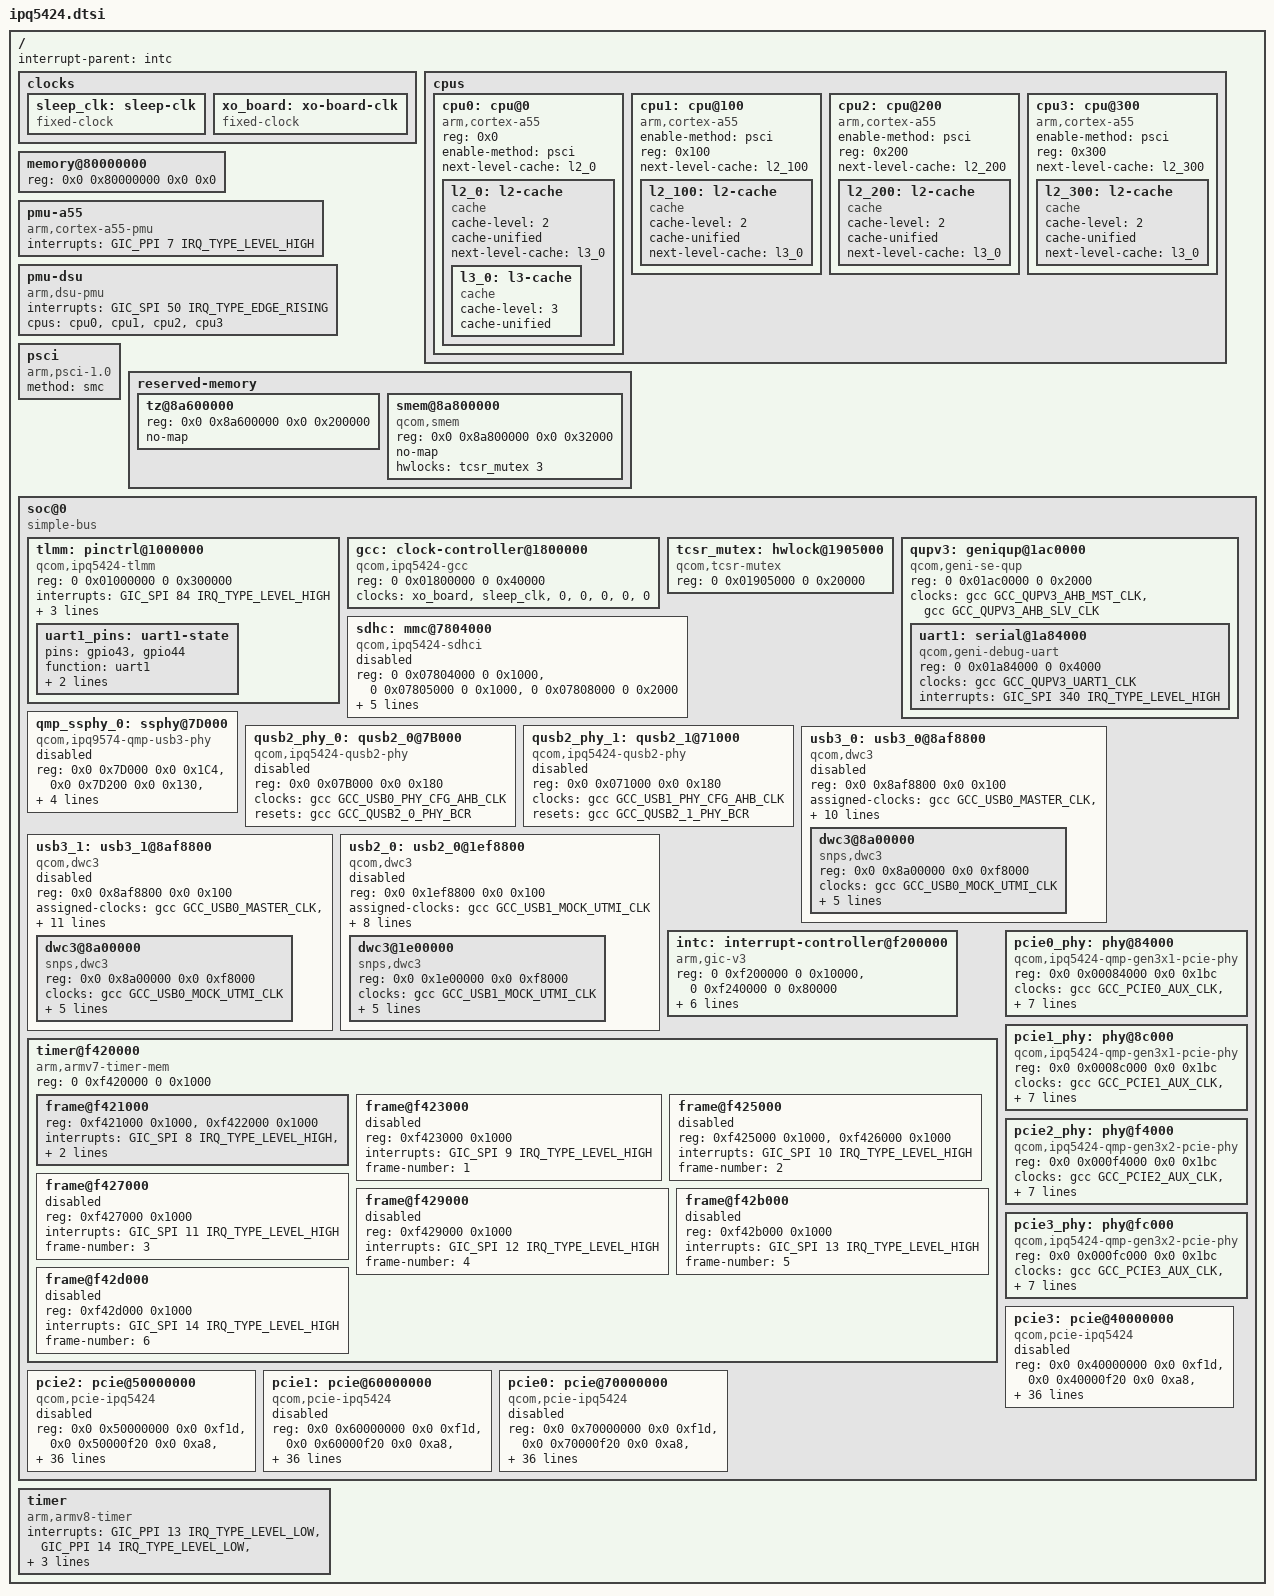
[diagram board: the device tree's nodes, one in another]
// SPDX-License-Identifier: (GPL-2.0+ OR BSD-3-Clause)
/*
 * IPQ5424 device tree source
 *
 * Copyright (c) 2020-2021 The Linux Foundation. All rights reserved.
 * Copyright (c) Qualcomm Technologies, Inc. and/or its subsidiaries.
 */

#include <dt-bindings/interrupt-controller/arm-gic.h>
#include <dt-bindings/clock/qcom,ipq5424-gcc.h>
#include <asm/arch/dt-bindings/clock/qcom,ipq5424-gcc.h>
#include <dt-bindings/reset/qcom,ipq5424-gcc.h>
#include <asm/arch/dt-bindings/reset/qcom,ipq5424-gcc.h>
#include <dt-bindings/net/qcom_ipqsoc.h>
#include <dt-bindings/gpio/gpio.h>

/ {
	#address-cells = <2>;
	#size-cells = <2>;
	interrupt-parent = <&intc>;

	clocks {
		sleep_clk: sleep-clk {
			compatible = "fixed-clock";
			#clock-cells = <0>;
		};

		xo_board: xo-board-clk {
			compatible = "fixed-clock";
			#clock-cells = <0>;
		};
	};

	cpus: cpus {
		#address-cells = <1>;
		#size-cells = <0>;

		cpu0: cpu@0 {
			device_type = "cpu";
			compatible = "arm,cortex-a55";
			reg = <0x0>;
			enable-method = "psci";
			next-level-cache = <&l2_0>;
			l2_0: l2-cache {
				compatible = "cache";
				cache-level = <2>;
				cache-unified;
				next-level-cache = <&l3_0>;

				l3_0: l3-cache {
					compatible = "cache";
					cache-level = <3>;
					cache-unified;
				};
			};
		};

		cpu1: cpu@100 {
			device_type = "cpu";
			compatible = "arm,cortex-a55";
			enable-method = "psci";
			reg = <0x100>;
			next-level-cache = <&l2_100>;

			l2_100: l2-cache {
				compatible = "cache";
				cache-level = <2>;
				cache-unified;
				next-level-cache = <&l3_0>;
			};
		};

		cpu2: cpu@200 {
			device_type = "cpu";
			compatible = "arm,cortex-a55";
			enable-method = "psci";
			reg = <0x200>;
			next-level-cache = <&l2_200>;

			l2_200: l2-cache {
				compatible = "cache";
				cache-level = <2>;
				cache-unified;
				next-level-cache = <&l3_0>;
			};
		};

		cpu3: cpu@300 {
			device_type = "cpu";
			compatible = "arm,cortex-a55";
			enable-method = "psci";
			reg = <0x300>;
			next-level-cache = <&l2_300>;

			l2_300: l2-cache {
				compatible = "cache";
				cache-level = <2>;
				cache-unified;
				next-level-cache = <&l3_0>;
			};
		};
	};

	memory@80000000 {
		device_type = "memory";
		/* We expect the bootloader to fill in the size */
		reg = <0x0 0x80000000 0x0 0x0>;
	};

	pmu-a55 {
		compatible = "arm,cortex-a55-pmu";
		interrupts = <GIC_PPI 7 IRQ_TYPE_LEVEL_HIGH>;
	};

	pmu-dsu {
		compatible = "arm,dsu-pmu";
		interrupts = <GIC_SPI 50 IRQ_TYPE_EDGE_RISING>;
		cpus = <&cpu0>, <&cpu1>, <&cpu2>, <&cpu3>;
	};

	psci {
		compatible = "arm,psci-1.0";
		method = "smc";
	};

	reserved-memory {
		#address-cells = <2>;
		#size-cells = <2>;
		ranges;

		tz@8a600000 {
			reg = <0x0 0x8a600000 0x0 0x200000>;
			no-map;
		};

		smem@8a800000 {
			compatible = "qcom,smem";
			reg = <0x0 0x8a800000 0x0 0x32000>;
			no-map;

			hwlocks = <&tcsr_mutex 3>;
		};
	};

	soc@0 {
		compatible = "simple-bus";
		#address-cells = <2>;
		#size-cells = <2>;
		ranges = <0 0 0 0 0x10 0>;

		tlmm: pinctrl@1000000 {
			compatible = "qcom,ipq5424-tlmm";
			reg = <0 0x01000000 0 0x300000>;
			interrupts = <GIC_SPI 84 IRQ_TYPE_LEVEL_HIGH>;
			gpio-controller;
			#gpio-cells = <2>;
			gpio-ranges = <&tlmm 0 0 50>;
			interrupt-controller;
			#interrupt-cells = <2>;

			uart1_pins: uart1-state {
				pins = "gpio43", "gpio44";
				function = "uart1";
				drive-strength = <8>;
				bias-pull-up;
			};
		};

		gcc: clock-controller@1800000 {
			compatible = "qcom,ipq5424-gcc";
			reg = <0 0x01800000 0 0x40000>;
			clocks = <&xo_board>,
				 <&sleep_clk>,
				 <0>,
				 <0>,
				 <0>,
				 <0>,
				 <0>;
			#clock-cells = <1>;
			#reset-cells = <1>;
			#interconnect-cells = <1>;
		};

		tcsr_mutex: hwlock@1905000 {
			compatible = "qcom,tcsr-mutex";
			reg = <0 0x01905000 0 0x20000>;
			#hwlock-cells = <1>;
		};

		qupv3: geniqup@1ac0000 {
			compatible = "qcom,geni-se-qup";
			reg = <0 0x01ac0000 0 0x2000>;
			ranges;
			clocks = <&gcc GCC_QUPV3_AHB_MST_CLK>,
				 <&gcc GCC_QUPV3_AHB_SLV_CLK>;
			clock-names = "m-ahb", "s-ahb";
			#address-cells = <2>;
			#size-cells = <2>;

			uart1: serial@1a84000 {
				compatible = "qcom,geni-debug-uart";
				reg = <0 0x01a84000 0 0x4000>;
				clocks = <&gcc GCC_QUPV3_UART1_CLK>;
				clock-names = "se";
				interrupts = <GIC_SPI 340 IRQ_TYPE_LEVEL_HIGH>;
			};
		};

		sdhc: mmc@7804000 {
			compatible = "qcom,ipq5424-sdhci", "qcom,sdhci-msm-v5";
			#address-cells = <2>;
			#size-cells = <2>;
			reg = <0 0x07804000 0 0x1000>,
				<0 0x07805000 0 0x1000>,
				<0 0x07808000 0 0x2000>;
			reg-names = "hc", "cqhci", "ice";

			interrupts = <GIC_SPI 116 IRQ_TYPE_LEVEL_HIGH>,
				     <GIC_SPI 119 IRQ_TYPE_LEVEL_HIGH>;
			interrupt-names = "hc_irq", "pwr_irq";

			clocks = <&gcc GCC_SDCC1_AHB_CLK>,
				 <&gcc GCC_SDCC1_APPS_CLK>,
				 <&xo_board>,
				 <&gcc GCC_SDCC1_ICE_CORE_CLK>;
			clock-names = "iface", "core", "xo", "ice";

			status = "disabled";
		};

		qmp_ssphy_0: ssphy@7D000 {
			compatible = "qcom,ipq9574-qmp-usb3-phy";
			#address-cells = <2>;
			#size-cells = <2>;
			reg = <0x0 0x7D000 0x0 0x1C4>,
				<0x0 0x7D200 0x0 0x130>,
				<0x0 0x7D400 0x0 0x200>,
				<0x0 0x7D800 0x0 0x1F8>;
			reg-names = "com_base", "tx_base",
				"rx_base", "pcs_base";
			clocks = <&gcc GCC_USB0_PIPE_CLK>;
			#phy-cells = <0>;
			resets =  <&gcc GCC_USB0_PHY_BCR>,
			       <&gcc GCC_USB3PHY_0_PHY_BCR>;
			status = "disabled";
		};

		qusb2_phy_0: qusb2_0@7B000 {
			compatible = "qcom,ipq5424-qusb2-phy",
					"qcom,ipq9574-qusb2-phy";
			#address-cells = <2>;
			#size-cells = <2>;
			reg = <0x0 0x07B000 0x0 0x180>;
			#phy-cells = <0>;
			clocks = <&gcc GCC_USB0_PHY_CFG_AHB_CLK>;
			clock-names = "cfg_ahb";

			resets = <&gcc GCC_QUSB2_0_PHY_BCR>;
			status = "disabled";
		};

		qusb2_phy_1: qusb2_1@71000 {
			compatible = "qcom,ipq5424-qusb2-phy",
					"qcom,ipq9574-qusb2-phy";
			#address-cells = <2>;
			#size-cells = <2>;
			reg = <0x0 0x071000 0x0 0x180>;
			#phy-cells = <0>;
			clocks = <&gcc GCC_USB1_PHY_CFG_AHB_CLK>;
			clock-names = "cfg_ahb";
			resets = <&gcc GCC_QUSB2_1_PHY_BCR>;
			status = "disabled";
		};

		usb3_0: usb3_0@8af8800 {
			compatible = "qcom,dwc3";
			reg = <0x0 0x8af8800 0x0 0x100>;
			#address-cells = <2>;
			#size-cells = <2>;
			assigned-clocks = <&gcc GCC_USB0_MASTER_CLK>,
				<&gcc GCC_USB0_MOCK_UTMI_CLK>,
				<&gcc GCC_USB0_AUX_CLK>;
			assigned-clock-rates = <200000000>,
				<24000000>,
				<24000000>;
			clocks = <&gcc GCC_USB0_MASTER_CLK>,
				<&gcc GCC_USB0_AUX_CLK>,
				<&gcc GCC_USB0_SLEEP_CLK>,
				<&gcc GCC_USB0_MOCK_UTMI_CLK>,
				<&gcc GCC_USB0_PHY_CFG_AHB_CLK>;
			clock-names = "master",
				"aux",
				"sleep",
				"ref",
				"cfg_ahb";
			resets = <&gcc GCC_USB_BCR>;
			ranges;
			status = "disabled";

			dwc3@8a00000 {
				compatible = "snps,dwc3";
				reg = <0x0 0x8a00000 0x0 0xf8000>;
				clocks = <&gcc GCC_USB0_MOCK_UTMI_CLK>;
				clock-names = "ref";
				dr_mode = "host";
				snps,dis_u2_susphy_quirk;
				snps,dis_u3_susphy_quirk;
				phys = <&qusb2_phy_0>, <&qmp_ssphy_0>;
				phy-names = "usb2-phy", "usb3-phy";
				maximum-speed = "super-speed";
			};
		};

		/*
		* usb3_1 node configuration makes usb 3.0 controller
		* to use usb 3.0 devices as usb 2.0 device
		*/
		usb3_1: usb3_1@8af8800 {
			compatible = "qcom,dwc3";
			reg = <0x0 0x8af8800 0x0 0x100>;
			#address-cells = <2>;
			#size-cells = <2>;
			assigned-clocks = <&gcc GCC_USB0_MASTER_CLK>,
				<&gcc GCC_USB0_MOCK_UTMI_CLK>,
				<&gcc GCC_USB0_AUX_CLK>;
			assigned-clock-rates = <200000000>,
				<24000000>,
				<24000000>;
			clocks = <&gcc GCC_USB0_MASTER_CLK>,
				<&gcc GCC_USB0_AUX_CLK>,
				<&gcc GCC_USB0_SLEEP_CLK>,
				<&gcc GCC_USB0_MOCK_UTMI_CLK>,
				<&gcc GCC_USB0_PHY_CFG_AHB_CLK>;
			clock-names = "master",
				"aux",
				"sleep",
				"ref",
				"cfg_ahb";
			resets = <&gcc GCC_USB_BCR>;
			ranges;
			qcom,select-utmi-as-pipe-clk;
			status = "disabled";

			dwc3@8a00000 {
				compatible = "snps,dwc3";
				reg = <0x0 0x8a00000 0x0 0xf8000>;
				clocks = <&gcc GCC_USB0_MOCK_UTMI_CLK>;
				clock-names = "ref";
				dr_mode = "host";
				snps,dis_u2_susphy_quirk;
				snps,dis_u3_susphy_quirk;
				phys = <&qusb2_phy_0>;
				phy-names = "usb2-phy";
				maximum-speed = "high-speed";
			};
		};

		usb2_0: usb2_0@1ef8800 {
			compatible = "qcom,dwc3";
			reg = <0x0 0x1ef8800 0x0 0x100>;
			#address-cells = <2>;
			#size-cells = <2>;
			assigned-clocks = <&gcc GCC_USB1_MOCK_UTMI_CLK>;
			assigned-clock-rates = <24000000>;
			clocks = <&gcc GCC_USB1_MASTER_CLK>,
				<&gcc GCC_CNOC_USB_CLK>,
				<&gcc GCC_USB1_SLEEP_CLK>,
				<&gcc GCC_USB1_MOCK_UTMI_CLK>,
				<&gcc GCC_USB1_PHY_CFG_AHB_CLK>;
			clock-names = "master",
				"snoc",
				"sleep",
				"ref",
				"cfg_ahb";
			resets = <&gcc GCC_USB1_BCR>;
			ranges;
			qcom,select-utmi-as-pipe-clk;
			status = "disabled";

			dwc3@1e00000 {
				compatible = "snps,dwc3";
				reg = <0x0 0x1e00000 0x0 0xf8000>;
				clocks = <&gcc GCC_USB1_MOCK_UTMI_CLK>;
				clock-names = "ref";
				dr_mode = "host";
				snps,dis_u2_susphy_quirk;
				snps,dis_u3_susphy_quirk;
				phys = <&qusb2_phy_1>;
				phy-names = "usb2-phy";
				maximum-speed = "high-speed";
			};
		};

		intc: interrupt-controller@f200000 {
			compatible = "arm,gic-v3";
			reg = <0 0xf200000 0 0x10000>, /* GICD */
			      <0 0xf240000 0 0x80000>; /* GICR * 4 regions */
			#interrupt-cells = <0x3>;
			interrupt-controller;
			#redistributor-regions = <1>;
			redistributor-stride = <0x0 0x20000>;
			interrupts = <GIC_PPI 9 IRQ_TYPE_LEVEL_HIGH>;
			mbi-ranges = <672 128>;
			msi-controller;
		};

		timer@f420000 {
			compatible = "arm,armv7-timer-mem";
			reg = <0 0xf420000 0 0x1000>;
			ranges = <0 0 0 0x10000000>;
			#address-cells = <1>;
			#size-cells = <1>;

			frame@f421000 {
				reg = <0xf421000 0x1000>,
				      <0xf422000 0x1000>;
				interrupts = <GIC_SPI 8 IRQ_TYPE_LEVEL_HIGH>,
					     <GIC_SPI 6 IRQ_TYPE_LEVEL_HIGH>;
				frame-number = <0>;
			};

			frame@f423000 {
				reg = <0xf423000 0x1000>;
				interrupts = <GIC_SPI 9 IRQ_TYPE_LEVEL_HIGH>;
				frame-number = <1>;
				status = "disabled";
			};

			frame@f425000 {
				reg = <0xf425000 0x1000>,
				      <0xf426000 0x1000>;
				interrupts = <GIC_SPI 10 IRQ_TYPE_LEVEL_HIGH>;
				frame-number = <2>;
				status = "disabled";
			};

			frame@f427000 {
				reg = <0xf427000 0x1000>;
				interrupts = <GIC_SPI 11 IRQ_TYPE_LEVEL_HIGH>;
				frame-number = <3>;
				status = "disabled";
			};

			frame@f429000 {
				reg = <0xf429000 0x1000>;
				interrupts = <GIC_SPI 12 IRQ_TYPE_LEVEL_HIGH>;
				frame-number = <4>;
				status = "disabled";
			};

			frame@f42b000 {
				reg = <0xf42b000 0x1000>;
				interrupts = <GIC_SPI 13 IRQ_TYPE_LEVEL_HIGH>;
				frame-number = <5>;
				status = "disabled";
			};

			frame@f42d000 {
				reg = <0xf42d000 0x1000>;
				interrupts = <GIC_SPI 14 IRQ_TYPE_LEVEL_HIGH>;
				frame-number = <6>;
				status = "disabled";
			};
		};

		pcie0_phy: phy@84000 {
			compatible = "qcom,ipq5424-qmp-gen3x1-pcie-phy",
				     "qcom,ipq9574-qmp-gen3x1-pcie-phy";
			reg = <0x0 0x00084000 0x0 0x1bc>; /* Serdes PLL */
			#address-cells = <1>;
			#size-cells = <1>;

			clocks = <&gcc GCC_PCIE0_AUX_CLK>,
				 <&gcc GCC_PCIE0_AHB_CLK>,
				 <&gcc GCC_PCIE0_RCHNG_CLK>,
				 <&gcc GCC_PCIE0_PIPE_CLK>,
				 <&gcc GCC_ANOC_PCIE0_1LANE_M_CLK>,
				 <&gcc GCC_CNOC_PCIE0_1LANE_S_CLK>;
			clock-names = "aux", "cfg_ahb", "rchng", "pipe",
					"lane_m", "lane_s";

			resets = <&gcc GCC_PCIE0_PHY_BCR>,
				 <&gcc GCC_PCIE0PHY_PHY_BCR>;
			reset-names = "phy", "common";

			#phy-cells = <0>;
			status = "okay";
		};

		pcie1_phy: phy@8c000 {
			compatible = "qcom,ipq5424-qmp-gen3x1-pcie-phy",
				     "qcom,ipq9574-qmp-gen3x1-pcie-phy";
			reg = <0x0 0x0008c000 0x0 0x1bc>; /* Serdes PLL */
			#address-cells = <1>;
			#size-cells = <1>;

			clocks = <&gcc GCC_PCIE1_AUX_CLK>,
				 <&gcc GCC_PCIE1_AHB_CLK>,
				 <&gcc GCC_PCIE1_RCHNG_CLK>,
				 <&gcc GCC_PCIE1_PIPE_CLK>,
				 <&gcc GCC_ANOC_PCIE1_1LANE_M_CLK>,
				 <&gcc GCC_CNOC_PCIE1_1LANE_S_CLK>;
			clock-names = "aux", "cfg_ahb", "rchng", "pipe",
					"lane_m", "lane_s";

			resets = <&gcc GCC_PCIE1_PHY_BCR>,
				 <&gcc GCC_PCIE1PHY_PHY_BCR>;
			reset-names = "phy", "common";

			#phy-cells = <0>;
			status = "okay";
		};

		pcie2_phy: phy@f4000 {
			compatible = "qcom,ipq5424-qmp-gen3x2-pcie-phy",
				     "qcom,ipq9574-qmp-gen3x2-pcie-phy";
			reg = <0x0 0x000f4000 0x0 0x1bc>; /* Serdes PLL */
			#address-cells = <1>;
			#size-cells = <1>;

			clocks = <&gcc GCC_PCIE2_AUX_CLK>,
				 <&gcc GCC_PCIE2_AHB_CLK>,
				 <&gcc GCC_PCIE2_RCHNG_CLK>,
				 <&gcc GCC_PCIE2_PIPE_CLK>,
				 <&gcc GCC_ANOC_PCIE2_2LANE_M_CLK>,
				 <&gcc GCC_CNOC_PCIE2_2LANE_S_CLK>;
			clock-names = "aux", "cfg_ahb","rchng", "pipe",
					 "lane_m", "lane_s";

			resets = <&gcc GCC_PCIE2_PHY_BCR>,
				 <&gcc GCC_PCIE2PHY_PHY_BCR>;
			reset-names = "phy", "common";

			#phy-cells = <0>;
			status = "okay";
		};

		pcie3_phy: phy@fc000 {
			compatible = "qcom,ipq5424-qmp-gen3x2-pcie-phy",
				     "qcom,ipq9574-qmp-gen3x2-pcie-phy";
			reg = <0x0 0x000fc000 0x0 0x1bc>; /* Serdes PLL */
			#address-cells = <1>;
			#size-cells = <1>;

			clocks = <&gcc GCC_PCIE3_AUX_CLK>,
				 <&gcc GCC_PCIE3_AHB_CLK>,
				 <&gcc GCC_PCIE3_RCHNG_CLK>,
				 <&gcc GCC_PCIE3_PIPE_CLK>,
				 <&gcc GCC_ANOC_PCIE3_2LANE_M_CLK>,
				 <&gcc GCC_CNOC_PCIE3_2LANE_S_CLK>;
			clock-names = "aux", "cfg_ahb", "rchng", "pipe",
					"lane_m", "lane_s";

			resets = <&gcc GCC_PCIE3_PHY_BCR>,
				 <&gcc GCC_PCIE3PHY_PHY_BCR>;
			reset-names = "phy", "common";

			#phy-cells = <0>;
			status = "okay";
		};

		/* 2L controller */
		pcie3: pcie@40000000 {
			compatible = "qcom,pcie-ipq5424";
			reg =  <0x0 0x40000000 0x0 0xf1d>,
			       <0x0 0x40000f20 0x0 0xa8>,
			       <0x0 0x40001000 0x0 0x1000>,
			       <0x0 0xf8000 0x0 0x3000>,
			       <0x0 0x40100000 0x0 0x1000>;
			reg-names = "dbi", "elbi", "atu", "parf", "config";
			device_type = "pci";
			linux,pci-domain = <3>;
			bus-range = <0x00 0xff>;
			num-lanes = <2>;
			#address-cells = <3>;
			#size-cells = <2>;
			axi-halt-val = <0x1e>; /* increase halt window size to 1GB */
			id = <3>;

			ranges = <0x81000000 0 0x40200000 0x0 0x40200000 0 0x00100000>,   /* downstream I/O */
				 <0x82000000 0 0x40300000 0x0 0x40300000 0 0x0fd00000>; /* non-prefetchable memory */

			#interrupt-cells = <1>;
			interrupt-map-mask = <0 0 0 0x7>;
			interrupt-map = <0 0 0 1 &intc 0 479 IRQ_TYPE_LEVEL_HIGH>, /* int_a */
					<0 0 0 2 &intc 0 480 IRQ_TYPE_LEVEL_HIGH>, /* int_b */
					<0 0 0 3 &intc 0 481 IRQ_TYPE_LEVEL_HIGH>, /* int_c */
					<0 0 0 4 &intc 0 482 IRQ_TYPE_LEVEL_HIGH>; /* int_d */

			interrupts = <GIC_SPI 478 IRQ_TYPE_LEVEL_HIGH>;
			interrupt-names = "global_irq";

			clocks = <&gcc GCC_PCIE3_AXI_M_CLK>,
				 <&gcc GCC_PCIE3_AXI_S_CLK>,
				 <&gcc GCC_PCIE3_AHB_CLK>,
				 <&gcc GCC_PCIE3_AUX_CLK>,
				 <&gcc GCC_PCIE3_AXI_S_BRIDGE_CLK>;

			clock-names = "axi_m",
				      "axi_s",
				      "ahb",
				      "aux",
				      "axi_bridge";

			assigned-clocks = <&gcc GCC_PCIE3_AUX_CLK>,
					<&gcc GCC_PCIE3_AXI_M_CLK>,
					<&gcc GCC_PCIE3_AXI_S_CLK>,
					<&gcc GCC_PCIE3_RCHNG_CLK>;

			assigned-clock-rates = <20000000>,
						<266666666>,
						<240000000>,
						<100000000>;

			resets = <&gcc GCC_PCIE3_PIPE_ARES>,
				 <&gcc GCC_PCIE3_CORE_STICKY_RESET>,
				 <&gcc GCC_PCIE3_AXI_M_ARES>,
				 <&gcc GCC_PCIE3_AXI_S_ARES>,
				 <&gcc GCC_PCIE3_AXI_M_STICKY_RESET>,
				 <&gcc GCC_PCIE3_AXI_S_STICKY_RESET>,
				 <&gcc GCC_PCIE3_AHB_ARES>,
				 <&gcc GCC_PCIE3_AUX_ARES>;

			reset-names = "pipe",
				      "sticky",
				      "axi_m",
				      "axi_s",
				      "axi_m_sticky",
				      "axi_s_sticky",
				      "ahb",
				      "aux";

			msi-parent = <&intc>;

			phys = <&pcie3_phy>;
			phy-names = "pciephy";

			status = "disabled";
		};

		/* 2L controller */
		pcie2: pcie@50000000 {
			compatible = "qcom,pcie-ipq5424";
			reg =  <0x0 0x50000000 0x0 0xf1d>,
			       <0x0 0x50000f20 0x0 0xa8>,
			       <0x0 0x50001000 0x0 0x1000>,
			       <0x0 0xf0000 0x0 0x3000>,
			       <0x0 0x50100000 0x0 0x1000>;
			reg-names = "dbi", "elbi", "atu", "parf", "config";
			device_type = "pci";
			linux,pci-domain = <2>;
			bus-range = <0x00 0xff>;
			num-lanes = <2>;
			#address-cells = <3>;
			#size-cells = <2>;
			axi-halt-val = <0x1e>; /* increase halt window size to 1GB */
			id = <2>;

			ranges = <0x81000000 0 0x50200000 0x0 0x50200000 0 0x00100000>,   /* downstream I/O */
				 <0x82000000 0 0x50300000 0x0 0x50300000 0 0x0fd00000>; /* non-prefetchable memory */

			#interrupt-cells = <1>;
			interrupt-map-mask = <0 0 0 0x7>;
			interrupt-map = <0 0 0 1 &intc 0 464 IRQ_TYPE_LEVEL_HIGH>, /* int_a */
					<0 0 0 2 &intc 0 465 IRQ_TYPE_LEVEL_HIGH>, /* int_b */
					<0 0 0 3 &intc 0 466 IRQ_TYPE_LEVEL_HIGH>, /* int_c */
					<0 0 0 4 &intc 0 467 IRQ_TYPE_LEVEL_HIGH>; /* int_d */

			interrupts = <GIC_SPI 463 IRQ_TYPE_LEVEL_HIGH>;
			interrupt-names = "global_irq";

			clocks = <&gcc GCC_PCIE2_AXI_M_CLK>,
				 <&gcc GCC_PCIE2_AXI_S_CLK>,
				 <&gcc GCC_PCIE2_AHB_CLK>,
				 <&gcc GCC_PCIE2_AUX_CLK>,
				 <&gcc GCC_PCIE2_AXI_S_BRIDGE_CLK>;

			clock-names = "axi_m",
				      "axi_s",
				      "ahb",
				      "aux",
				      "axi_bridge";

			assigned-clocks = <&gcc GCC_PCIE2_AUX_CLK>,
					<&gcc GCC_PCIE2_AXI_M_CLK>,
					<&gcc GCC_PCIE2_AXI_S_CLK>,
					<&gcc GCC_PCIE2_RCHNG_CLK>;

			assigned-clock-rates = <20000000>,
						<266666666>,
						<240000000>,
						<100000000>;

			resets = <&gcc GCC_PCIE2_PIPE_ARES>,
				 <&gcc GCC_PCIE2_CORE_STICKY_RESET>,
				 <&gcc GCC_PCIE2_AXI_M_ARES>,
				 <&gcc GCC_PCIE2_AXI_S_ARES>,
				 <&gcc GCC_PCIE2_AXI_M_STICKY_RESET>,
				 <&gcc GCC_PCIE2_AXI_S_STICKY_RESET>,
				 <&gcc GCC_PCIE2_AHB_ARES>,
				 <&gcc GCC_PCIE2_AUX_ARES>;

			reset-names = "pipe",
				      "sticky",
				      "axi_m",
				      "axi_s",
				      "axi_m_sticky",
				      "axi_s_sticky",
				      "ahb",
				      "aux";

			msi-parent = <&intc>;

			phys = <&pcie2_phy>;
			phy-names = "pciephy";

			status = "disabled";
		};

		/* 1L controller */
		pcie1: pcie@60000000 {
			compatible = "qcom,pcie-ipq5424";
			reg =  <0x0 0x60000000 0x0 0xf1d>,
			       <0x0 0x60000f20 0x0 0xa8>,
			       <0x0 0x60001000 0x0 0x1000>,
			       <0x0 0x88000 0x0 0x3000>,
			       <0x0 0x60100000 0x0 0x1000>;
			reg-names = "dbi", "elbi", "atu", "parf", "config";
			device_type = "pci";
			linux,pci-domain = <1>;
			bus-range = <0x00 0xff>;
			num-lanes = <1>;
			#address-cells = <3>;
			#size-cells = <2>;
			axi-halt-val = <0x1e>; /* increase halt window size to 1GB */
			id = <1>;

			ranges = <0x81000000 0 0x60200000 0x0 0x60200000 0 0x00100000>,   /* downstream I/O */
				 <0x82000000 0 0x60300000 0x0 0x60300000 0 0x0fd00000>; /* non-prefetchable memory */

			#interrupt-cells = <1>;
			interrupt-map-mask = <0 0 0 0x7>;
			interrupt-map = <0 0 0 1 &intc 0 449 IRQ_TYPE_LEVEL_HIGH>, /* int_a */
					<0 0 0 2 &intc 0 450 IRQ_TYPE_LEVEL_HIGH>, /* int_b */
					<0 0 0 3 &intc 0 451 IRQ_TYPE_LEVEL_HIGH>, /* int_c */
					<0 0 0 4 &intc 0 452 IRQ_TYPE_LEVEL_HIGH>; /* int_d */

			interrupts = <GIC_SPI 448 IRQ_TYPE_LEVEL_HIGH>;
			interrupt-names = "global_irq";

			clocks = <&gcc GCC_PCIE1_AXI_M_CLK>,
				 <&gcc GCC_PCIE1_AXI_S_CLK>,
				 <&gcc GCC_PCIE1_AHB_CLK>,
				 <&gcc GCC_PCIE1_AUX_CLK>,
				 <&gcc GCC_PCIE1_AXI_S_BRIDGE_CLK>;

			clock-names = "axi_m",
				      "axi_s",
				      "ahb",
				      "aux",
				      "axi_bridge";

			assigned-clocks = <&gcc GCC_PCIE1_AUX_CLK>,
					<&gcc GCC_PCIE1_AXI_M_CLK>,
					<&gcc GCC_PCIE1_AXI_S_CLK>,
					<&gcc GCC_PCIE1_RCHNG_CLK>;

			assigned-clock-rates = <20000000>,
						<240000000>,
						<240000000>,
						<100000000>;

			resets = <&gcc GCC_PCIE1_PIPE_ARES>,
				 <&gcc GCC_PCIE1_CORE_STICKY_RESET>,
				 <&gcc GCC_PCIE1_AXI_M_ARES>,
				 <&gcc GCC_PCIE1_AXI_S_ARES>,
				 <&gcc GCC_PCIE1_AXI_M_STICKY_RESET>,
				 <&gcc GCC_PCIE1_AXI_S_STICKY_RESET>,
				 <&gcc GCC_PCIE1_AHB_ARES>,
				 <&gcc GCC_PCIE1_AUX_ARES>;

			reset-names = "pipe",
				      "sticky",
				      "axi_m",
				      "axi_s",
				      "axi_m_sticky",
				      "axi_s_sticky",
				      "ahb",
				      "aux";

			msi-parent = <&intc>;

			phys = <&pcie1_phy>;
			phy-names = "pciephy";

			status = "disabled";
		};

		/* 1L controller */
		pcie0: pcie@70000000 {
			compatible = "qcom,pcie-ipq5424";
			reg =  <0x0 0x70000000 0x0 0xf1d>,
			       <0x0 0x70000f20 0x0 0xa8>,
			       <0x0 0x70001000 0x0 0x1000>,
			       <0x0 0x80000 0x0 0x3000>,
			       <0x0 0x70100000 0x0 0x1000>;
			reg-names = "dbi", "elbi", "atu", "parf", "config";
			device_type = "pci";
			linux,pci-domain = <0>;
			bus-range = <0x00 0xff>;
			num-lanes = <1>;
			#address-cells = <3>;
			#size-cells = <2>;
			axi-halt-val = <0x1e>; /* increase halt window size to 1GB */
			id = <0>;

			ranges = <0x81000000 0 0x70200000 0x0 0x70200000 0 0x00100000>,   /* downstream I/O */
				 <0x82000000 0 0x70300000 0x0 0x70300000 0 0x0fd00000>; /* non-prefetchable memory */

			#interrupt-cells = <1>;
			interrupt-map-mask = <0 0 0 0x7>;
			interrupt-map = <0 0 0 1 &intc 0 434 IRQ_TYPE_LEVEL_HIGH>, /* int_a */
					<0 0 0 2 &intc 0 435 IRQ_TYPE_LEVEL_HIGH>, /* int_b */
					<0 0 0 3 &intc 0 436 IRQ_TYPE_LEVEL_HIGH>, /* int_c */
					<0 0 0 4 &intc 0 437 IRQ_TYPE_LEVEL_HIGH>; /* int_d */

			interrupts = <GIC_SPI 433 IRQ_TYPE_LEVEL_HIGH>;
			interrupt-names = "global_irq";

			clocks = <&gcc GCC_PCIE0_AXI_M_CLK>,
				 <&gcc GCC_PCIE0_AXI_S_CLK>,
				 <&gcc GCC_PCIE0_AHB_CLK>,
				 <&gcc GCC_PCIE0_AUX_CLK>,
				 <&gcc GCC_PCIE0_AXI_S_BRIDGE_CLK>;

			clock-names = "axi_m",
				      "axi_s",
				      "ahb",
				      "aux",
				      "axi_bridge";

			assigned-clocks = <&gcc GCC_PCIE0_AUX_CLK>,
					<&gcc GCC_PCIE0_AXI_M_CLK>,
					<&gcc GCC_PCIE0_AXI_S_CLK>,
					<&gcc GCC_PCIE0_RCHNG_CLK>;

			assigned-clock-rates = <20000000>,
						<240000000>,
						<240000000>,
						<100000000>;

			resets = <&gcc GCC_PCIE0_PIPE_ARES>,
				 <&gcc GCC_PCIE0_CORE_STICKY_RESET>,
				 <&gcc GCC_PCIE0_AXI_M_ARES>,
				 <&gcc GCC_PCIE0_AXI_S_ARES>,
				 <&gcc GCC_PCIE0_AXI_M_STICKY_RESET>,
				 <&gcc GCC_PCIE0_AXI_S_STICKY_RESET>,
				 <&gcc GCC_PCIE0_AHB_ARES>,
				 <&gcc GCC_PCIE0_AUX_ARES>;

			reset-names = "pipe",
				      "sticky",
				      "axi_m",
				      "axi_s",
				      "axi_m_sticky",
				      "axi_s_sticky",
				      "ahb",
				      "aux";

			msi-parent = <&intc>;

			phys = <&pcie0_phy>;
			phy-names = "pciephy";

			status = "disabled";
		};

	};

	timer {
		compatible = "arm,armv8-timer";
		interrupts = <GIC_PPI 13 IRQ_TYPE_LEVEL_LOW>,
			     <GIC_PPI 14 IRQ_TYPE_LEVEL_LOW>,
			     <GIC_PPI 11 IRQ_TYPE_LEVEL_LOW>,
			     <GIC_PPI 10 IRQ_TYPE_LEVEL_LOW>,
			     <GIC_PPI 12 IRQ_TYPE_LEVEL_LOW>;
	};
};

